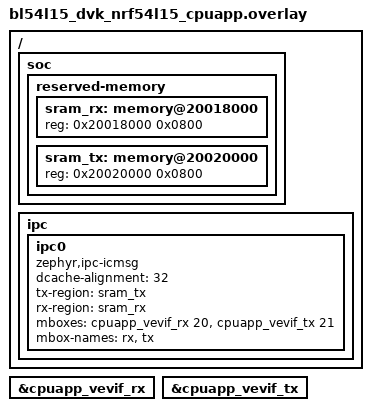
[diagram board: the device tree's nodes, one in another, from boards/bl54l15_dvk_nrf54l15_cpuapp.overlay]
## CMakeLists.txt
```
#
# Copyright (c) 2022 Nordic Semiconductor ASA
#
# SPDX-License-Identifier: Apache-2.0
#

cmake_minimum_required(VERSION 3.28.0)

find_package(Zephyr REQUIRED HINTS $ENV{ZEPHYR_BASE})

if(CONFIG_BOARD_APARD32690_MAX32690_M4 OR
   CONFIG_BOARD_EK_RA8P1_R7KA8P1KFLCAC_CM85 OR
   CONFIG_BOARD_NRF5340BSIM_NRF5340_CPUAPP OR
   CONFIG_BOARD_NRF5340DK_NRF5340_CPUAPP OR
   CONFIG_BOARD_NRF54L15DK_NRF54L15_CPUAPP OR
   CONFIG_BOARD_NRF54LM20DK_NRF54LM20A_CPUAPP OR
   CONFIG_BOARD_NRF54LV10DK_NRF54LV10A_CPUAPP OR
   CONFIG_BOARD_NRF7120DK_NRF7120_CPUAPP OR
   CONFIG_BOARD_NUCLEO_H755ZI_Q_STM32H755XX_M7 OR
   CONFIG_BOARD_STM32H747I_DISCO)
  message(STATUS "${BOARD}/${BOARD_QUALIFIERS} compile as HOST in this sample")
else()
  message(FATAL_ERROR "${BOARD}/${BOARD_QUALIFIERS} is not supported for this sample")
endif()

project(ipc_service_host)

target_include_directories(app PRIVATE ${CMAKE_CURRENT_SOURCE_DIR}/common)

target_sources(app PRIVATE src/main.c)

include(ExternalProject)
```

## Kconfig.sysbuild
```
# Copyright 2023 Nordic Semiconductor ASA
#
# SPDX-License-Identifier: Apache-2.0

source "share/sysbuild/Kconfig"

config REMOTE_BOARD
string
	default "$(BOARD)/max32690/rv32" if SOC_MAX32690_M4
	default "ek_ra8p1/r7ka8p1kflcac/cm33" if $(BOARD) = "ek_ra8p1"
	default "nrf5340bsim/nrf5340/cpunet" if $(BOARD) = "nrf5340bsim"
	default "nrf5340dk/nrf5340/cpunet" if $(BOARD) = "nrf5340dk"
	default "nrf54l15dk/nrf54l15/cpuflpr" if $(BOARD) = "nrf54l15dk"
	default "nrf54lm20dk/nrf54lm20a/cpuflpr" if $(BOARD) = "nrf54lm20dk"
	default "$(BOARD)/nrf54lv10a/cpuflpr" if SOC_NRF54LV10A_CPUAPP
	default "nrf7120dk/nrf7120/cpuflpr" if "$(BOARD)/$(BOARD_QUALIFIERS)" = "nrf7120dk/nrf7120/cpuapp"
	default "nrf7120dk/nrf7120e/cpuflpr" if "$(BOARD)/$(BOARD_QUALIFIERS)" = "nrf7120dk/nrf7120e/cpuapp"
	default "nucleo_h755zi_q/stm32h755xx/m4" if $(BOARD) = "nucleo_h755zi_q"
	default "stm32h747i_disco/stm32h747xx/m4" if $(BOARD) = "stm32h747i_disco"
```

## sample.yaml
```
sample:
  name: IPC Service example integration (icmsg backend)
common:
  timeout: 30
  sysbuild: true
  tags: ipc
  harness: pytest
tests:
  sample.ipc.icmsg:
    platform_allow:
      - nrf5340bsim/nrf5340/cpuapp
      - nrf5340dk/nrf5340/cpuapp
    integration_platforms:
      - nrf5340dk/nrf5340/cpuapp
      - nrf5340bsim/nrf5340/cpuapp

  sample.ipc.icmsg.nrf54l:
    platform_allow:
      - nrf54l15dk/nrf54l15/cpuapp
      - nrf54lm20dk/nrf54lm20a/cpuapp
    integration_platforms:
      - nrf54l15dk/nrf54l15/cpuapp
    extra_args: icmsg_SNIPPET=nordic-flpr

  sample.ipc.icmsg.nrf54l_no_multithreading:
    platform_allow:
      - nrf54l15dk/nrf54l15/cpuapp
      - nrf54lm20dk/nrf54lm20a/cpuapp
    integration_platforms:
      - nrf54l15dk/nrf54l15/cpuapp
    extra_args:
      - icmsg_SNIPPET=nordic-flpr
      - icmsg_CONFIG_MULTITHREADING=n
      - icmsg_CONFIG_LOG_MODE_MINIMAL=y
      - remote_CONFIG_MULTITHREADING=n
      - remote_CONFIG_LOG_MODE_MINIMAL=y

  sample.ipc.icmsg.nrf54l_remote_no_multithreading:
    platform_allow:
      - nrf54l15dk/nrf54l15/cpuapp
      - nrf54lm20dk/nrf54lm20a/cpuapp
    integration_platforms:
      - nrf54l15dk/nrf54l15/cpuapp
    extra_args:
      - icmsg_SNIPPET=nordic-flpr
      - remote_CONFIG_MULTITHREADING=n
      - remote_CONFIG_LOG_MODE_MINIMAL=y

  sample.ipc.icbmsg.nrf54l:
    platform_allow:
      - nrf54l15dk/nrf54l15/cpuapp
      - nrf54lm20dk/nrf54lm20a/cpuapp
    integration_platforms:
      - nrf54l15dk/nrf54l15/cpuapp
    extra_args:
      - icmsg_SNIPPET=nordic-flpr
      - icmsg_CONFIG_IPC_SERVICE_BACKEND_ICBMSG_NUM_EP=1
      - icmsg_EXTRA_DTC_OVERLAY_FILE="boards/nrf54l_cpuapp_icbmsg.overlay"
      - remote_CONFIG_IPC_SERVICE_BACKEND_ICBMSG_NUM_EP=1
      - remote_EXTRA_DTC_OVERLAY_FILE="boards/nrf54l_cpuflpr_icbmsg.overlay"

  sample.ipc.icbmsg.nrf54l_no_multithreading:
    platform_allow:
      - nrf54l15dk/nrf54l15/cpuapp
      - nrf54lm20dk/nrf54lm20a/cpuapp
    integration_platforms:
      - nrf54l15dk/nrf54l15/cpuapp
    extra_args:
      - icmsg_SNIPPET=nordic-flpr
      - icmsg_CONFIG_IPC_SERVICE_BACKEND_ICBMSG_NUM_EP=1
      - icmsg_EXTRA_DTC_OVERLAY_FILE="boards/nrf54l_cpuapp_icbmsg.overlay"
      - icmsg_CONFIG_MULTITHREADING=n
      - icmsg_CONFIG_LOG_MODE_MINIMAL=y
      - remote_CONFIG_IPC_SERVICE_BACKEND_ICBMSG_NUM_EP=1
      - remote_EXTRA_DTC_OVERLAY_FILE="boards/nrf54l_cpuflpr_icbmsg.overlay"
      - remote_CONFIG_MULTITHREADING=n
      - remote_CONFIG_LOG_MODE_MINIMAL=y

  sample.ipc.icbmsg.nrf54l_remote_no_multithreading:
    platform_allow:
      - nrf54l15dk/nrf54l15/cpuapp
      - nrf54lm20dk/nrf54lm20a/cpuapp
    integration_platforms:
      - nrf54l15dk/nrf54l15/cpuapp
    extra_args:
      - icmsg_SNIPPET=nordic-flpr
      - icmsg_CONFIG_IPC_SERVICE_BACKEND_ICBMSG_NUM_EP=1
      - icmsg_EXTRA_DTC_OVERLAY_FILE="boards/nrf54l_cpuapp_icbmsg.overlay"
      - remote_CONFIG_IPC_SERVICE_BACKEND_ICBMSG_NUM_EP=1
      - remote_EXTRA_DTC_OVERLAY_FILE="boards/nrf54l_cpuflpr_icbmsg.overlay"
      - remote_CONFIG_MULTITHREADING=n
      - remote_CONFIG_LOG_MODE_MINIMAL=y

  sample.ipc.icmsg.nrf7120:
    platform_allow:
      - nrf7120dk/nrf7120/cpuapp
    integration_platforms:
      - nrf7120dk/nrf7120/cpuapp
    extra_args: icmsg_SNIPPET=nordic-flpr

  sample.ipc.icbmsg.nrf7120:
    platform_allow:
      - nrf7120dk/nrf7120/cpuapp
    integration_platforms:
      - nrf7120dk/nrf7120/cpuapp
    extra_args:
      - icmsg_SNIPPET=nordic-flpr
      - icmsg_CONFIG_IPC_SERVICE_BACKEND_ICBMSG_NUM_EP=1
      - icmsg_EXTRA_DTC_OVERLAY_FILE="boards/nrf7120dk_nrf7120_cpuapp_icbmsg.overlay"
      - remote_CONFIG_IPC_SERVICE_BACKEND_ICBMSG_NUM_EP=1
      - remote_EXTRA_DTC_OVERLAY_FILE="boards/nrf7120dk_nrf7120_cpuflpr_icbmsg.overlay"
```

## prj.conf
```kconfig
CONFIG_PRINTK=y

CONFIG_IPC_SERVICE=y
CONFIG_MBOX=y

CONFIG_LOG=y
CONFIG_ASSERT=y
```

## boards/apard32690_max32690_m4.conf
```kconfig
# Copyright (c) 2026 Analog Devices, Inc.
# SPDX-License-Identifier: Apache-2.0
CONFIG_MAX32_SECONDARY_RV32=y
```

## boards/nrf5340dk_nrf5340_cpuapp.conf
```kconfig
CONFIG_SOC_NRF53_CPUNET_ENABLE=y
CONFIG_MBOX_NRFX_IPC=y
```

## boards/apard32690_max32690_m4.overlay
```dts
/*
 * Copyright (c) 2026 Analog Devices, Inc.
 *
 * SPDX-License-Identifier: Apache-2.0
 */

/ {
	ipc {
		ipc0: ipc0 {
			compatible = "zephyr,ipc-icmsg";
			dcache-alignment = <32>;
			tx-region = <&sram8_tx>;
			rx-region = <&sram8_rx>;
			mboxes = <&mbox 0 &mbox 0>;
			mbox-names = "tx", "rx";
			status = "okay";
		};
	};

	/* Use the upper half of SRAM8 for RX/TX, since the
	 * lower half is reserved for the RV32 core's data
	 */
	sram8_rx: memory@20110000 {
		compatible = "mmio-sram";
		reg = <0x20110000 DT_SIZE_K(32)>;
	};

	sram8_tx: memory@20118000 {
		compatible = "mmio-sram";
		reg = <0x20118000 DT_SIZE_K(32)>;
	};
};

&mbox {
	status = "okay";
};
```

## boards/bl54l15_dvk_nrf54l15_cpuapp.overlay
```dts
/*
 * Copyright (c) 2024 Nordic Semiconductor ASA
 * Copyright (c) 2025 Ezurio LLC
 *
 * SPDX-License-Identifier: Apache-2.0
 */

/ {
	soc {
		reserved-memory {
			#address-cells = <1>;
			#size-cells = <1>;

			sram_rx: memory@20018000 {
				reg = <0x20018000 0x0800>;
			};

			sram_tx: memory@20020000 {
				reg = <0x20020000 0x0800>;
			};
		};
	};

	ipc {
		ipc0: ipc0 {
			compatible = "zephyr,ipc-icmsg";
			dcache-alignment = <32>;
			tx-region = <&sram_tx>;
			rx-region = <&sram_rx>;
			mboxes = <&cpuapp_vevif_rx 20>, <&cpuapp_vevif_tx 21>;
			mbox-names = "rx", "tx";
			status = "okay";
		};
	};
};

&cpuapp_vevif_rx {
	status = "okay";
};

&cpuapp_vevif_tx {
	status = "okay";
};
```

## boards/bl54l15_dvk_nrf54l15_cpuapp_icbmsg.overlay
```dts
/*
 * Copyright (c) 2024 Nordic Semiconductor ASA
 * Copyright (c) 2025 Ezurio LLC
 *
 * SPDX-License-Identifier: Apache-2.0
 */

/ {
	soc {
		reserved-memory {
			#address-cells = <1>;
			#size-cells = <1>;

			sram_rx: memory@20018000 {
				reg = <0x20018000 0x0800>;
			};

			sram_tx: memory@20020000 {
				reg = <0x20020000 0x0800>;
			};
		};
	};

	ipc {
		ipc0: ipc0 {
			compatible = "zephyr,ipc-icbmsg";
			dcache-alignment = <32>;
			tx-region = <&sram_tx>;
			rx-region = <&sram_rx>;
			tx-blocks = <16>;
			rx-blocks = <18>;
			mboxes = <&cpuapp_vevif_rx 20>, <&cpuapp_vevif_tx 21>;
			mbox-names = "rx", "tx";
			status = "okay";
		};
	};
};

&cpuapp_vevif_rx {
	status = "okay";
};

&cpuapp_vevif_tx {
	status = "okay";
};
```

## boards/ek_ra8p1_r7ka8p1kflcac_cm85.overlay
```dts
/*
 * Copyright (c) 2025-2026 Renesas Electronics Corporation
 * SPDX-License-Identifier: Apache-2.0
 */

/ {
	ipc {
		ipc0: ipc0 {
			compatible = "zephyr,ipc-icmsg";
			dcache-alignment = <32>;
			tx-region = <&sram_tx>;
			rx-region = <&sram_rx>;
			mboxes = <&mbox0 0>, <&mbox0 0>;
			mbox-names = "rx", "tx";
			status = "okay";
		};
	};

	soc {
		/* Define shared memory regions for IPC */
		reserved-memory {
			#address-cells = <1>;
			#size-cells = <1>;

			sram_rx: memory@2219f000 {
				reg = <0x2219f000 0x800>;
			};

			sram_tx: memory@2219f800 {
				reg = <0x2219f800 0x800>;
			};
		};
	};
};

/* Redefine sram size for CPU1 */
&sram1 {
	reg = <0x22100000 DT_SIZE_K(636)>;
};

&mbox0 {
	interrupts = <94 1>;
	status = "okay";
};
```

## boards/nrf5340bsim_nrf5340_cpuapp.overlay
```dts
/*
 * Copyright (c) 2024 Nordic Semiconductor ASA
 *
 * SPDX-License-Identifier: Apache-2.0
 */

#include "nrf5340dk_nrf5340_cpuapp.overlay"
```

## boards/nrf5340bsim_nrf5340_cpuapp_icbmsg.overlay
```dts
/*
 * Copyright (c) 2022 Nordic Semiconductor ASA
 *
 * SPDX-License-Identifier: Apache-2.0
 */

/ {
	chosen {
		/delete-property/ zephyr,ipc_shm;
	};

	reserved-memory {
		/delete-node/ memory@20070000;

		sram_tx: memory@20070000 {
			reg = <0x20070000 0x0800>;
		};

		sram_rx: memory@20078000 {
			reg = <0x20078000 0x0800>;
		};
	};

	ipc {
		/delete-node/ ipc0;

		ipc0: ipc0 {
			compatible = "zephyr,ipc-icbmsg";
			tx-region = <&sram_tx>;
			rx-region = <&sram_rx>;
			mboxes = <&mbox 0>, <&mbox 1>;
			mbox-names = "tx", "rx";
			tx-blocks = <16>;
			rx-blocks = <18>;
			status = "okay";

			bt_hci_ipc0: bt_hci_ipc0 {
				compatible = "zephyr,bt-hci-ipc";
				status = "okay";
			};
		};
	};
};
```

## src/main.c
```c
/*
 * Copyright (c) 2022 Nordic Semiconductor ASA
 *
 * SPDX-License-Identifier: Apache-2.0
 */

#include <zephyr/kernel.h>
#include <zephyr/device.h>

#include <zephyr/ipc/ipc_service.h>
#if defined(CONFIG_SOC_NRF5340_CPUAPP)
#include <nrf53_cpunet_mgmt.h>
#endif
#include <string.h>

#include "common.h"

#include <zephyr/logging/log.h>
LOG_MODULE_REGISTER(host, LOG_LEVEL_INF);

#if DT_HAS_ALIAS(dut_ipc)
#define IPC_NODE DT_ALIAS(dut_ipc)
#else
#define IPC_NODE DT_NODELABEL(ipc0)
#endif

#if defined(CONFIG_MULTITHREADING)
K_SEM_DEFINE(bound_sem, 0, 1);
#else
volatile uint32_t bound_sem = 1;
volatile uint32_t recv_sem = 1;
#endif

static unsigned char expected_message = 'A';
static size_t expected_len = PACKET_SIZE_START;
static size_t received;

static void ep_bound(void *priv)
{
	received = 0;
#if defined(CONFIG_MULTITHREADING)
	k_sem_give(&bound_sem);
#else
	bound_sem = 0;
#endif
	LOG_INF("Ep bounded");
}

static void ep_unbound(void *priv)
{
	LOG_INF("Ep unbounded");
}

static void ep_recv(const void *data, size_t len, void *priv)
{
#if defined(CONFIG_ASSERT)
	struct data_packet *packet = (struct data_packet *)data;

	__ASSERT(packet->data[0] == expected_message, "Unexpected message. Expected %c, got %c",
		expected_message, packet->data[0]);
	__ASSERT(len == expected_len, "Unexpected length. Expected %zu, got %zu",
		expected_len, len);
#endif

#ifndef CONFIG_MULTITHREADING
	recv_sem = 0;
#endif

	received += len;
	expected_message++;
	expected_len++;

	if (expected_message > 'Z') {
		expected_message = 'A';
	}

	if (expected_len > sizeof(struct data_packet)) {
		expected_len = PACKET_SIZE_START;
	}
}

static void ep_error(const char *message, void *priv)
{
	LOG_ERR("ICMsg error: %s", message);
}

static int send_for_time(struct ipc_ept *ep, const int64_t sending_time_ms)
{
	struct data_packet msg = {.data[0] = 'a'};
	size_t mlen = PACKET_SIZE_START;
	size_t bytes_sent = 0;
	int ret = 0;

	LOG_INF("Perform sends for %lld [ms]", sending_time_ms);

	int64_t start = k_uptime_get();

	while ((k_uptime_get() - start) < sending_time_ms) {
		ret = ipc_service_send(ep, &msg, mlen);
		if (ret == -ENOMEM) {
			/* No space in the buffer. Retry. */
			ret = 0;
			continue;
		} else if (ret < 0) {
			LOG_ERR("Failed to send (%c) failed with ret %d", msg.data[0], ret);
			break;
		}
#if !defined(CONFIG_MULTITHREADING)
		else {
			recv_sem = 1;
		}
#endif

		msg.data[0]++;
		if (msg.data[0] > 'z') {
			msg.data[0] = 'a';
		}

		bytes_sent += mlen;
		mlen++;

		if (mlen > sizeof(struct data_packet)) {
			mlen = PACKET_SIZE_START;
		}

#if defined(CONFIG_MULTITHREADING)
		k_usleep(1);
#else
		while ((recv_sem != 0) && ((k_uptime_get() - start) < sending_time_ms)) {
		};
#endif
	}

	LOG_INF("Sent %zu [Bytes] over %lld [ms]", bytes_sent, sending_time_ms);

	return ret;
}

static struct ipc_ept_cfg ep_cfg = {
	.cb = {
		.bound    = ep_bound,
		.unbound  = ep_unbound,
		.received = ep_recv,
		.error    = ep_error,
	},
};

int main(void)
{
	const struct device *ipc0_instance;
	struct ipc_ept ep;
	int ret;

	LOG_INF("IPC-service HOST demo started");

	ipc0_instance = DEVICE_DT_GET(IPC_NODE);

	ret = ipc_service_open_instance(ipc0_instance);
	if ((ret < 0) && (ret != -EALREADY)) {
		LOG_ERR("ipc_service_open_instance() failure");
		return ret;
	}

	ret = ipc_service_register_endpoint(ipc0_instance, &ep, &ep_cfg);
	if (ret < 0) {
		LOG_ERR("ipc_service_register_endpoint() failure");
		return ret;
	}

#if defined(CONFIG_MULTITHREADING)
	k_sem_take(&bound_sem, K_FOREVER);
#else
	while (bound_sem != 0) {
	};
#endif

	ret = send_for_time(&ep, SENDING_TIME_MS);
	if (ret < 0) {
		LOG_ERR("send_for_time() failure");
		return ret;
	}

	LOG_INF("Wait 500ms. Let remote core finish its sends");
#if defined(CONFIG_MULTITHREADING)
	k_msleep(500);
#else
	k_busy_wait(500000);
#endif

	LOG_INF("Received %zu [Bytes] in total", received);

#if defined(CONFIG_SOC_NRF5340_CPUAPP)
	LOG_INF("Stop network core");
	nrf53_cpunet_enable(false);

	LOG_INF("Reset IPC service");

	ret = ipc_service_deregister_endpoint(&ep);
	if (ret != 0) {
		LOG_ERR("ipc_service_register_endpoint() failure");
		return ret;
	}

	/* Reset message and expected message value and len. */
	expected_message = 'A';
	expected_len = PACKET_SIZE_START;

	/* Reset bound sem. */
	ret = k_sem_init(&bound_sem, 0, 1);
	if (ret != 0) {
		LOG_ERR("k_sem_init() failure");
		return ret;
	}

	ret = ipc_service_register_endpoint(ipc0_instance, &ep, &ep_cfg);
	if (ret != 0) {
		LOG_INF("ipc_service_register_endpoint() failure");
		return ret;
	}

	LOG_INF("Run network core");
	nrf53_cpunet_enable(true);

	k_sem_take(&bound_sem, K_FOREVER);

	ret = send_for_time(&ep, SENDING_TIME_MS);
	if (ret < 0) {
		LOG_ERR("send_for_time() failure");
		return ret;
	}
#endif /* CONFIG_SOC_NRF5340_CPUAPP */

	LOG_INF("IPC-service HOST demo ended");

	return 0;
}
```
